# PIC32MX250F256L device description
Architecture: MIPS; Family: PIC32MX; Series: PIC32MX
Registers are 32-bit, read-write, no defined reset value unless marked. A register's access mark holds for its fields unless they carry their own. Offsets are from the block's base; [hi:lo] are bit positions; {n}, {i} and the like mark numbered series; 'fields as' and 'values as' point back to an identical list.

## RCON
Instances: RCON 0x1f80f600 in periph1
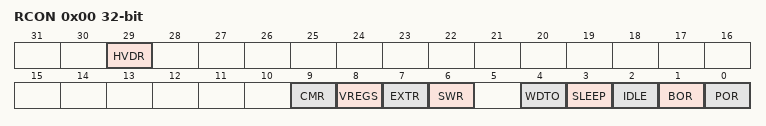
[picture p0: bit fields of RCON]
0x00 RCON — Reset Control Register
  [29] HVDR — High Voltage Detect Reset Flag bit
    1=High Voltage Detect (HVD) Reset has occurred; 0=HVD Reset has not occurred
  [9] CMR — Configuration Mismatch Reset Flag bit
    1=Configuration mismatch Reset has occurred; 0=Configuration mismatch Reset has not occurred
  [8] VREGS — Voltage Regulator Standby Enable bit
    1=Regulator is enabled and is on during Sleep mode; 0=Regulator is set to Stand-by Tracking mode
  [7] EXTR — External Reset Pin Flag bit
    1=Master Clear (pin) Reset has occurred; 0=Master Clear (pin) Reset has not occurred
  [6] SWR — Software Reset Flag bit
    1=Software Reset was executed; 0=Software Reset as not executed
  [4] WDTO — Watchdog Timer Time-out Flag bit
    1=WDT Time-out has occurred; 0=WDT Time-out has not occurred
  [3] SLEEP — Wake From Sleep Flag bit
    1=Device was in Sleep mode; 0=Device was not in Sleep mode
  [2] IDLE — Wake From Idle Flag bit
    1=Device was in Idle mode; 0=Device was not in Idle mode
  [1] BOR — Brown-out Reset Flag bit
    1=Brown-out Reset has occurred; 0=Brown-out Reset has not occurred
  [0] POR — Power-on Reset Flag bit
    1=Power-on Reset has occurred; 0=Power-on Reset has not occurred
0x10 RSWRST — Software Reset Register
  [0] SWRST — Software Reset Trigger bit
    1=Enable software Reset event; 0=No effect

## RPIN
Instances: RPIN 0x1f80fa04 in periph1
0x00 INT1R — Peripheral Pin Select Input Register
  [3:0] INT1R
0x04 INT2R — Peripheral Pin Select Input Register
  [3:0] INT2R
0x08 INT3R — Peripheral Pin Select Input Register
  [3:0] INT3R
0x0C INT4R — Peripheral Pin Select Input Register
  [3:0] INT4R
{0xC+4i} T{i}CKR (i=2..5) — Peripheral Pin Select Input Register
  [3:0] T{i}CKR
{0x20+4i} IC{i}R (i=1..8) — Peripheral Pin Select Input Register
  [3:0] IC{i}R
0x44 OCFAR — Peripheral Pin Select Input Register
  [3:0] OCFAR
0x48 OCFBR — Peripheral Pin Select Input Register
  [3:0] OCFBR
{0x44+8i} U{i}RXR (i=1..6) — Peripheral Pin Select Input Register
  [3:0] U{i}RXR
{0x48+8i} U{i}CTSR (i=1..6) — Peripheral Pin Select Input Register
  [3:0] U{i}CTSR
{0x74+0xC*i} SDI{i}R (i=1..6) — Peripheral Pin Select Input Register
  [3:0] SDI{i}R
{0x78+0xC*i} SS{i}R (i=1..6) — Peripheral Pin Select Input Register
  [3:0] SS{i}R
0xC4 C1RXR — Peripheral Pin Select Input Register
  [3:0] C1RXR
0xC8 C2RXR — Peripheral Pin Select Input Register
  [3:0] C2RXR
0xCC REFCLKIR — Peripheral Pin Select Input Register
  [3:0] REFCLKIR
{0xC8+4i} REFI{i}R (i=2..4) — Peripheral Pin Select Input Register
  [3:0] REFI{i}R

## RPOR
Instances: RPOR 0x1f80fb00 in periph1
{0x0+4i} RPA{i}R (i=0..15)
  [3:0] RPA{i}R
{0x40+4i} RPB{i}R (i=0..15)
  [3:0] RPB{i}R
{0x80+4i} RPC{i}R (i=0..15)
  [3:0] RPC{i}R
{0xC0+4i} RPD{i}R (i=0..15)
  [3:0] RPD{i}R
{0x100+4i} RPE{i}R (i=0..15)
  [3:0] RPE{i}R
{0x140+4i} RPF{i}R (i=0..15)
  [3:0] RPF{i}R
{0x180+4i} RPG{i}R (i=0..15)
  [3:0] RPG{i}R

## RTCC
Instances: RTCC 0x1f800200 in periph0
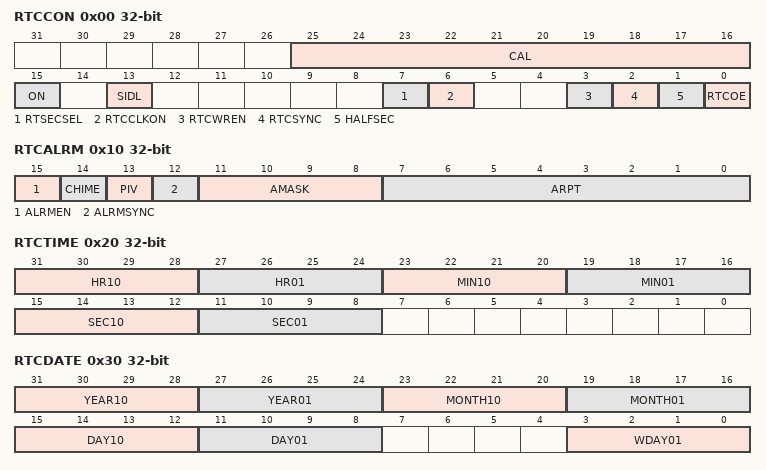
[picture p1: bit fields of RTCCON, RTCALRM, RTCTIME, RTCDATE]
0x00 RTCCON — RTC Control Register
  [25:16] CAL — RTC Drift Calibration bits
    0x1ff=Maximum positive adjustment, adds 511 RTC clock pulses every one minute; 1=Minimum positive adjustment, adds 1 RTC clock pulse every one minute; 0=No adjustment; 0x3ff=Minimum negative adjustment, subtracts 1 RTC clock pulse every one minute; 0x200=Maximum negative adjustment, subtracts 512 clock pulses every one minute
  [15] ON — RTCC On bit
    1=RTCC module is enabled; 0=RTCC module is disabled
  [13] SIDL — Stop in Idle Mode bit
    1=Disables the PBCLK to the RTCC when CPU enters in Idle mode; 0=Continue normal operation in Idle mode
  [7] RTSECSEL — RTCC Seconds Clock Output Select bit
    1=RTCC Seconds Clock is selected for the RTCC pin; 0=RTCC Alarm Pulse is selected for the RTCC pin
  [6] RTCCLKON — RTCC Clock Enable Status bit
    1=RTCC Clock is actively running; 0=RTCC Clock is not running
  [3] RTCWREN — RTC Value Registers Write Enable bit
    1=RTC Value registers can be written to by the user; 0=RTC Value registers are locked out from being written to by the user
  [2] RTCSYNC — RTCC Value Registers Read Synchronization bit
    1=RTC Value registers can change while reading due to a rollover ripple that results in an invalid data read; 0=RTC Value registers can be read without concern about a rollover ripple
  [1] HALFSEC — Half-Second Status bit
    1=Second half period of a second; 0=First half period of a second
  [0] RTCOE — RTCC Output Enable bit
    1=RTCC clock output is enabled clock presented onto an I/O; 0=RTCC clock output is disabled
0x10 RTCALRM — RTC ALARM Control Register
  [15] ALRMEN — Alarm Enable bit
    1=Alarm is enabled; 0=Alarm is disabled
  [14] CHIME — Chime Enable bit
    1=Chime is enabled ARPT(7:0) is allowed to rollover from 0x00 to 0xFF; 0=Chime is disabled ARPT(7:0) stops once it reaches 0x00
  [13] PIV — Alarm Pulse Initial Value bit
    1=(When ALRMEN = 0) Alarm pulse high / (When ALRMEN = 1) PIV is read-only and returns state of the alarm pulse; 0=(When ALRMEN = 0) Alarm pulse low / (When ALRMEN = 1) PIV is read-only and returns state of the alarm pulse
  [12] ALRMSYNC — Alarm Sync bit
    1=ARPT(7:0) and ALRMEN may change as a result of a half second rollover during a read; 0=ARPT(7:0) and ALRMEN can be read without concerns of rollover because the prescaler is more than 32 RTC clocks away from a half-second rollover
  [11:8] AMASK — Alarm Mask Configuration bits
    0=Every half-second; 1=Every second; 2=Every 10 seconds; 3=Every minute; 4=Every 10 minutes; 5=Every hour; 6=Once a day; 7=Once a week; 8=Once a month; 9=Once a year (except when configured for February 29; {v}=Reserved; do not use (v=10..15)
  [7:0] ARPT — Alarm Repeat Counter Value bits
    {v}=Alarm will trigger {v+1} times (v=0..255)
0x20 RTCTIME — RTC Time Value Register
  [31:28] HR10, [27:24] HR01, [23:20] MIN10, [19:16] MIN01, [15:12] SEC10, [11:8] SEC01
0x30 RTCDATE — RTC Date Value Register
  [31:28] YEAR10, [27:24] YEAR01, [23:20] MONTH10, [19:16] MONTH01, [15:12] DAY10, [11:8] DAY01, [3:0] WDAY01
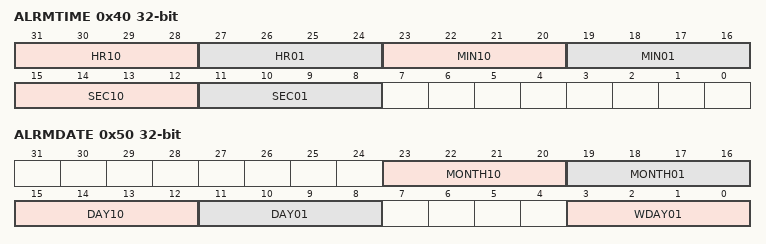
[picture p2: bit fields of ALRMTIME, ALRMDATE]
0x40 ALRMTIME — Alarm Time Value Register
  fields as RTCTIME
0x50 ALRMDATE — Alarm Date Value Register
  [23:20] MONTH10, [19:16] MONTH01, [15:12] DAY10, [11:8] DAY01, [3:0] WDAY01

## TMR1
Instances: TMR1 0x1f800600 in periph0
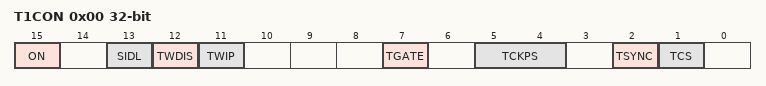
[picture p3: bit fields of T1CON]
0x00 T1CON — TYPE A TIMER CONTROL REGISTER
  [15] ON — Timer On bit
    1=Timer is enabled; 0=Timer is disabled
  [13] SIDL — Stop in Idle Mode bit
    1=Discontinue operation when device enters Idle mode; 0=Continue operation even in Idle mode
  [12] TWDIS — Asynchronous Timer Write Disable bit
    1=Writes to TMR1 are ignored until pending write operation completes; 0=Back-to-back writes are enabled (Legacy Asynchronous Timer functionality)
  [11] TWIP — Asynchronous Timer Write in Progress bit
    1=(In Asynchronous Timer mode) Asynchronous write to TMR1 register in progress / (in synchronous mode) read as 0; 0=(In Asynchronous Timer mode) Asynchronous write to TMR1 register complete / (in synchronous mode) read as 0
  [7] TGATE — Timer Gated Time Accumulation Enable bit
    1=(When TCS is 0) Gated time accumulation is enabled / (When TCS is 1) bit is ignored; 0=(When TCS is 0) Gated time accumulation is disabled / (When TCS is 1) bit is ignored
  [5:4] TCKPS — Timer Input Clock Prescale Select bits
    3=1:256 prescale value; 2=1:64 prescale value; 1=1:8 prescale value; 0=1:1 prescale value
  [2] TSYNC — Timer External Clock Input Synchronization Selection bit
    1=(When TCS is 1) External clock input is synchronized / (When TCS is 0) bit is ignored; 0=(When TCS is 1) External clock input is not synchronized / (When TCS is 0) bit is ignored
  [1] TCS — Timer Clock Source Select bit
    1=External clock from T1CKI pin; 0=Internal peripheral clock
0x10 TMR1
0x20 PR1

## TMR
Instances: TMR 0x1f800800 in periph0
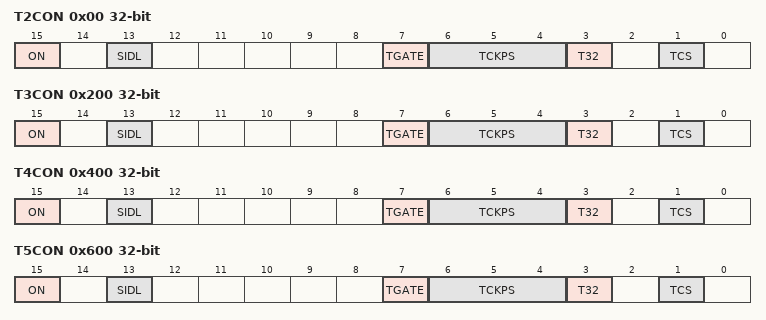
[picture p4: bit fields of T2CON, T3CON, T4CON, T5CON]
0x00 T2CON — Type B Timer Control Register
  [15] ON — Timer On bit
    1=Module is enabled; 0=Module is disabled
  [13] SIDL — Stop in Idle Mode bit
    1=Discontinue operation when device enters Idle mode; 0=Continue operation even in Idle mode
  [7] TGATE — Timer Gated Time Accumulation Enable bit
    1=(When TCS is 1): This bit is ignored and is read as 0 / (When TCS=0): Gated time accumulation is enabled; 0=(When TCS is 1): This bit is ignored and is read as 0 / (When TCS=0): Gated time accumulation is disabled
  [6:4] TCKPS — Timer Input Clock Prescale Select bits
    7=1:256 prescale value; 6=1:64 prescale value; 5=1:32 prescale value; 4=1:16 prescale value; 3=1:8 prescale value; 2=1:4 prescale value; 1=1:2 prescale value; 0=1:1 prescale value
  [3] T32 — 32-Bit Timer Mode Select bit
    1=Odd numbered and even numbered timers form a 32-bit timer; 0=Odd numbered and even numbered timers form separate 16-bit timers
  [1] TCS — Timer Clock Source Select bit
    1=External clock from TxCK pin; 0=Internal peripheral clock
0x10 TMR2
0x20 PR2
0x200 T3CON — Type B Timer Control Register
  fields as T2CON
0x210 TMR3
0x220 PR3
0x400 T4CON — Type B Timer Control Register
  fields as T2CON
0x410 TMR4
0x420 PR4
0x600 T5CON — Type B Timer Control Register
  fields as T2CON
0x610 TMR5
0x620 PR5

## WDT
Instances: WDT 0x1f800000 in periph0
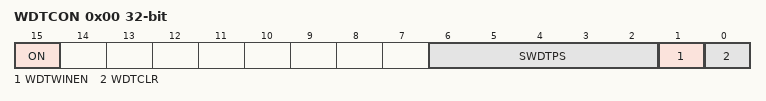
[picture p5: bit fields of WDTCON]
0x00 WDTCON — Watchdog Timer Control Register
  [15] ON — Watchdog Timer Enable bit
    1=Enables the WDT if it is not enabled by the device configuration; 0=Disable the WDT if it was enabled in software
  [6:2] SWDTPS
  [1] WDTWINEN — Watchdog Timer Window Enable bit
    1=Enable windowed Watchdog Timer; 0=Disable windowed Watchdog Timer
  [0] WDTCLR — Watchdog Timer Reset bit
    1=Writing a 1 will clear the WDT; 0=Software cannot force this bit to a 0

## Notices in the file
Copyright (c) 2019 Microchip Technology Inc.
SPDX-License-Identifier: Apache-2.0
Licensed under the Apache License, Version 2.0 (the "License");
you may not use this file except in compliance with the License.
You may obtain a copy of the License at
http://www.apache.org/licenses/LICENSE-2.0
Unless required by applicable law or agreed to in writing, software
distributed under the License is distributed on an "AS IS" BASIS,
WITHOUT WARRANTIES OR CONDITIONS OF ANY KIND, either express or implied.
See the License for the specific language governing permissions and
limitations under the License.
